# PLL register map
Vendor: Texas Instruments
Peripheral module from a debugger description file (folder 66AK2G0x_66AK2G1x).
Registers are 32-bit, access per field, reset values left out (the file's numbers can be read two ways) unless marked. A register's access mark holds for its fields unless they carry their own. Offsets are as the file gives them; lines under a group give offsets from that group; [hi:lo] are bit positions; {n}, {i} and the like mark numbered series; 'fields as' and 'values as' point back to an identical list; <NAME> marks a mode.

## PLL
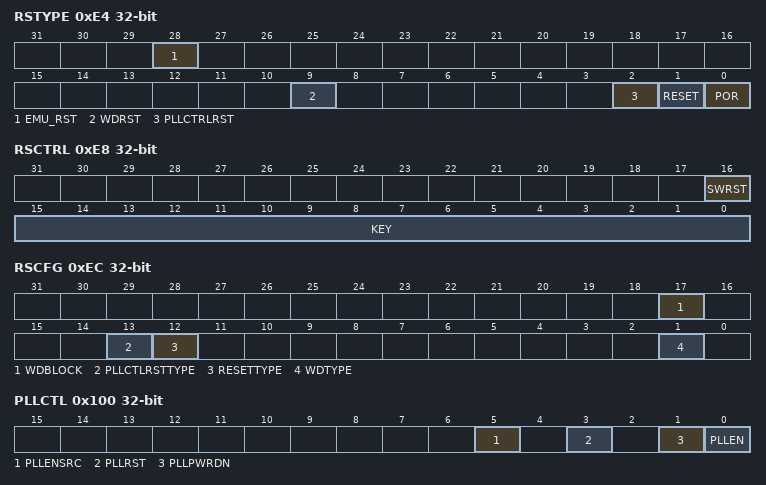
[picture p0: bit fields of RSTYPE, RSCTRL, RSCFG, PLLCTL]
0xE4 RSTYPE ro
  [28] EMU_RST — Reset initiated by emulation.
  [9] WDRST — Reset initiated by Watchdog Timer(s).
  [2] PLLCTRLRST — Reset initiated by PLL Controller (software reset).
  [1] RESET — RESET pin reset.
  [0] POR — Power-on reset.
0xE8 RSCTRL
  [16] SWRST rw — Software reset.
  [15:0] KEY rw — Key used to enable writes toRSCTRL and RSCFG.
0xEC RSCFG
  [17] WDBLOCK rw — Block Watchdog timers reset:
  [13] PLLCTLRSTTYPE rw — PLL Controller initiates a software driven reset of type:
  [12] RESETTYPE rw — RESET pin initiates a reset of type:
  [1] WDTYPE rw — Watchdog Timers initiate a reset of type:
0xF0 RSISO
  [27:0] MOD_ISO_N rw — Isolate Module domain[N].
0x100 PLLCTL
  [5] PLLENSRC ro — PLL enable source bit.
  [3] PLLRST rw — PLL reset bit.
  [1] PLLPWRDN rw — PLL power-down mode select bit.
  [0] PLLEN rw — PLL enable bit.
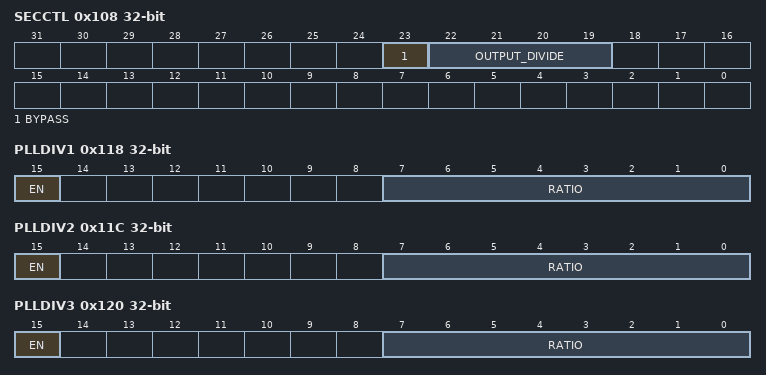
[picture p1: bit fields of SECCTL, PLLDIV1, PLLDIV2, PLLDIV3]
0x108 SECCTL
  [23] BYPASS rw — PLL Bypass Enable.
  [22:19] OUTPUT_DIVIDE rw — Output Divider ratio bits.
0x110 PLLM
  [5:0] PLLM rw — PLL multiplier bits. Defines the frequency multiplier of the input reference clock.
0x118 PLLDIV1
  [15] EN rw — Divider Dnenable bit.
  [7:0] RATIO rw — Divider ratio bits.
0x11C PLLDIV2
  fields as PLLDIV1
0x120 PLLDIV3
  [15] EN rw — Divider 3 enable bit.
  [7:0] RATIO rw — Divider ratio bits.
0x138 PLLCMD
  [0] GOSET rw — GO operation command for SYSCLK rate change and phase alignment. Before setting this bit to initiate a GO operation, check the GOSTAT bit in thePLLSTAT register to ensure all previous GO operations have completed.
0x13C PLLSTAT ro
  [0] GOSTAT — GO operation status.
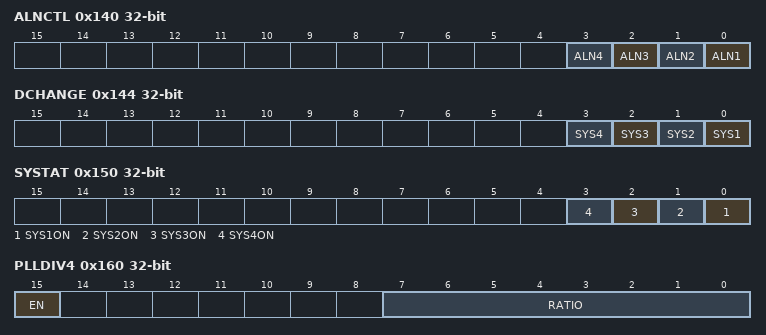
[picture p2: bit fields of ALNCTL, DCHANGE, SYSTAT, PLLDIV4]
0x140 ALNCTL
  [n-1] ALN{n} rw (n=1..4) — SYSCLK{n} alignment.
0x144 DCHANGE
  [n-1] SYS{n} rw (n=1..4) — Identifies when the SYSCLK{n} divide ratio has been modified.
0x150 SYSTAT ro
  [n-1] SYS{n}ON (n=1..4) — SYSCLK{n} on status.
0x160 PLLDIV4
  [15] EN rw — Divider 4 enable bit.
  [7:0] RATIO rw — Divider ratio bits.
